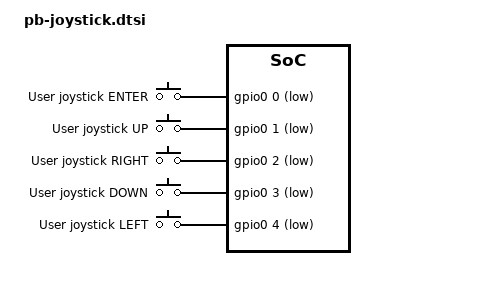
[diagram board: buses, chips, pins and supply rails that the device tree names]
/*
 * Copyright (c) 2023-2025 TiaC Systems
 * SPDX-License-Identifier: Apache-2.0
 */

#include <zephyr/dt-bindings/input/input-event-codes.h>
#include <zephyr/dt-bindings/lvgl/lvgl.h>
#include <zephyr/dt-bindings/gpio/gpio.h>

/ {
	aliases {
		sw0 = &joystick_enter;
		sw1 = &joystick_up;
		sw2 = &joystick_right;
		sw3 = &joystick_down;
		sw4 = &joystick_left;
	};

	lvgl_keypad: lvgl-keypad {
		compatible = "zephyr,lvgl-keypad-input";
		input = <&gpio_keys>;
		input-codes = <INPUT_KEY_LEFT INPUT_KEY_RIGHT
			       INPUT_KEY_UP INPUT_KEY_DOWN
			       INPUT_KEY_ENTER>;
		lvgl-codes = <LV_KEY_LEFT LV_KEY_RIGHT
			      LV_KEY_UP LV_KEY_DOWN
			      LV_KEY_ENTER>;
	};

	gpio_keys: gpio_keys {
		compatible = "gpio-keys";
		status = "okay";

		joystick_enter: joystick_enter {
			gpios = <&gpio0 0 (GPIO_PULL_UP | GPIO_ACTIVE_LOW)>;
			zephyr,code = <INPUT_KEY_ENTER>;
			label = "User joystick ENTER";
		};
		joystick_up: joystick_up {
			gpios = <&gpio0 1 (GPIO_PULL_UP | GPIO_ACTIVE_LOW)>;
			zephyr,code = <INPUT_KEY_UP>;
			label = "User joystick UP";
		};
		joystick_right: joystick_right {
			gpios = <&gpio0 2 (GPIO_PULL_UP | GPIO_ACTIVE_LOW)>;
			zephyr,code = <INPUT_KEY_RIGHT>;
			label = "User joystick RIGHT";
		};
		joystick_down: joystick_down {
			gpios = <&gpio0 3 (GPIO_PULL_UP | GPIO_ACTIVE_LOW)>;
			zephyr,code = <INPUT_KEY_DOWN>;
			label = "User joystick DOWN";
		};
		joystick_left: joystick_left {
			gpios = <&gpio0 4 (GPIO_PULL_UP | GPIO_ACTIVE_LOW)>;
			zephyr,code = <INPUT_KEY_LEFT>;
			label = "User joystick LEFT";
		};
	};
};

&gpio0 {
	status = "okay";
};
